VERSION "created by canmatrix"

NS_ :

BS_:

BU_: User ADM_PC_LL25 ADM_PC_BC25 ADM_PC_BP25 ADM_PC_BI25

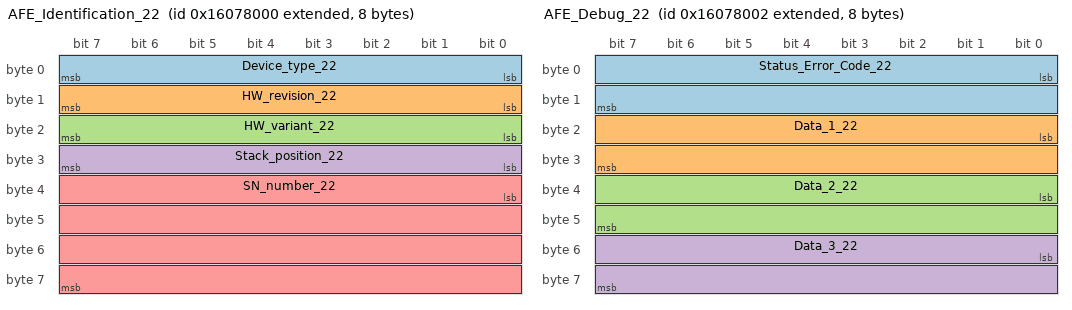
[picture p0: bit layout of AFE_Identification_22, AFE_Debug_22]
BO_ 2517073920 AFE_Identification_22: 8 ADM_PC_BP25
 SG_ Device_type_22 : 0|8@1+ (1,0) [0|255] "" Vector__XXX
 SG_ HW_revision_22 : 8|8@1+ (1,0) [0|255] "" Vector__XXX
 SG_ HW_variant_22 : 16|8@1+ (1,0) [0|255] "" Vector__XXX
 SG_ Stack_position_22 : 24|8@1+ (1,0) [0|255] "" Vector__XXX
 SG_ SN_number_22 : 32|32@1+ (1,0) [0|4294967295] "" Vector__XXX

BO_ 2517073921 AFE_FwInfo_22: 8 ADM_PC_BP25
 SG_ FW_info_mux_22 M : 56|8@1+ (1,0) [0|255] "" Vector__XXX
 SG_ FW_revision_0_22 m0 : 0|8@1+ (1,0) [0|255] "" Vector__XXX
 SG_ FW_revision_1_22 m0 : 8|8@1+ (1,0) [0|255] "" Vector__XXX
 SG_ FW_revision_2_22 m0 : 16|8@1+ (1,0) [0|255] "" Vector__XXX
 SG_ FW_revision_3_22 m0 : 24|8@1+ (1,0) [0|255] "" Vector__XXX
 SG_ FW_revision_4_22 m0 : 32|8@1+ (1,0) [0|255] "" Vector__XXX
 SG_ FW_revision_5_22 m0 : 40|8@1+ (1,0) [0|255] "" Vector__XXX
 SG_ FW_revision_6_22 m0 : 48|8@1+ (1,0) [0|255] "" Vector__XXX
 SG_ FW_revision_7_22 m1 : 0|8@1+ (1,0) [0|255] "" Vector__XXX
 SG_ FW_revision_8_22 m1 : 8|8@1+ (1,0) [0|255] "" Vector__XXX
 SG_ FW_revision_9_22 m1 : 16|8@1+ (1,0) [0|255] "" Vector__XXX
 SG_ FW_revision_10_22 m1 : 24|8@1+ (1,0) [0|255] "" Vector__XXX
 SG_ FW_revision_11_22 m1 : 32|8@1+ (1,0) [0|255] "" Vector__XXX
 SG_ FW_revision_12_22 m1 : 40|8@1+ (1,0) [0|255] "" Vector__XXX
 SG_ FW_revision_13_22 m1 : 48|8@1+ (1,0) [0|255] "" Vector__XXX
 SG_ FW_datecode_0_22 m2 : 0|8@1+ (1,0) [0|255] "" Vector__XXX
 SG_ FW_datecode_1_22 m2 : 8|8@1+ (1,0) [0|255] "" Vector__XXX
 SG_ FW_datecode_2_22 m2 : 16|8@1+ (1,0) [0|255] "" Vector__XXX
 SG_ FW_datecode_3_22 m2 : 24|8@1+ (1,0) [0|255] "" Vector__XXX
 SG_ FW_datecode_4_22 m2 : 32|8@1+ (1,0) [0|255] "" Vector__XXX
 SG_ FW_datecode_5_22 m2 : 40|8@1+ (1,0) [0|255] "" Vector__XXX
 SG_ FW_datecode_6_22 m2 : 48|8@1+ (1,0) [0|255] "" Vector__XXX
 SG_ FW_datecode_7_22 m3 : 0|8@1+ (1,0) [0|255] "" Vector__XXX
 SG_ FW_datecode_8_22 m3 : 8|8@1+ (1,0) [0|255] "" Vector__XXX
 SG_ FW_datecode_9_22 m3 : 16|8@1+ (1,0) [0|255] "" Vector__XXX
 SG_ FW_datecode_10_22 m3 : 24|8@1+ (1,0) [0|255] "" Vector__XXX
 SG_ FW_datecode_11_22 m3 : 32|8@1+ (1,0) [0|255] "" Vector__XXX
 SG_ FW_datecode_12_22 m3 : 40|8@1+ (1,0) [0|255] "" Vector__XXX
 SG_ FW_datecode_13_22 m3 : 48|8@1+ (1,0) [0|255] "" Vector__XXX

BO_ 2517073933 _AFE_Boot_FwInfo_22: 8 ADM_PC_BP25
 SG_ Boot_FW_info_mux_22 M : 56|8@1+ (1,0) [0|255] "" Vector__XXX
 SG_ FW_revision_0_22 m0 : 0|8@1+ (1,0) [0|255] "" Vector__XXX
 SG_ FW_revision_1_22 m0 : 8|8@1+ (1,0) [0|255] "" Vector__XXX
 SG_ FW_revision_2_22 m0 : 16|8@1+ (1,0) [0|255] "" Vector__XXX
 SG_ FW_revision_3_22 m0 : 24|8@1+ (1,0) [0|255] "" Vector__XXX
 SG_ FW_revision_4_22 m0 : 32|8@1+ (1,0) [0|255] "" Vector__XXX
 SG_ FW_revision_5_22 m0 : 40|8@1+ (1,0) [0|255] "" Vector__XXX
 SG_ FW_revision_6_22 m0 : 48|8@1+ (1,0) [0|255] "" Vector__XXX
 SG_ FW_revision_7_22 m1 : 0|8@1+ (1,0) [0|255] "" Vector__XXX
 SG_ FW_revision_8_22 m1 : 8|8@1+ (1,0) [0|255] "" Vector__XXX
 SG_ FW_revision_9_22 m1 : 16|8@1+ (1,0) [0|255] "" Vector__XXX
 SG_ FW_revision_10_22 m1 : 24|8@1+ (1,0) [0|255] "" Vector__XXX
 SG_ FW_revision_11_22 m1 : 32|8@1+ (1,0) [0|255] "" Vector__XXX
 SG_ FW_revision_12_22 m1 : 40|8@1+ (1,0) [0|255] "" Vector__XXX
 SG_ FW_revision_13_22 m1 : 48|8@1+ (1,0) [0|255] "" Vector__XXX
 SG_ FW_datecode_0_22 m2 : 0|8@1+ (1,0) [0|255] "" Vector__XXX
 SG_ FW_datecode_1_22 m2 : 8|8@1+ (1,0) [0|255] "" Vector__XXX
 SG_ FW_datecode_2_22 m2 : 16|8@1+ (1,0) [0|255] "" Vector__XXX
 SG_ FW_datecode_3_22 m2 : 24|8@1+ (1,0) [0|255] "" Vector__XXX
 SG_ FW_datecode_4_22 m2 : 32|8@1+ (1,0) [0|255] "" Vector__XXX
 SG_ FW_datecode_5_22 m2 : 40|8@1+ (1,0) [0|255] "" Vector__XXX
 SG_ FW_datecode_6_22 m2 : 48|8@1+ (1,0) [0|255] "" Vector__XXX
 SG_ FW_datecode_7_22 m3 : 0|8@1+ (1,0) [0|255] "" Vector__XXX
 SG_ FW_datecode_8_22 m3 : 8|8@1+ (1,0) [0|255] "" Vector__XXX
 SG_ FW_datecode_9_22 m3 : 16|8@1+ (1,0) [0|255] "" Vector__XXX
 SG_ FW_datecode_10_22 m3 : 24|8@1+ (1,0) [0|255] "" Vector__XXX
 SG_ FW_datecode_11_22 m3 : 32|8@1+ (1,0) [0|255] "" Vector__XXX
 SG_ FW_datecode_12_22 m3 : 40|8@1+ (1,0) [0|255] "" Vector__XXX
 SG_ FW_datecode_13_22 m3 : 48|8@1+ (1,0) [0|255] "" Vector__XXX

BO_ 2517073922 AFE_Debug_22: 8 ADM_PC_BP25
 SG_ Status_Error_Code_22 : 0|16@1+ (1,0) [0|65535] "" Vector__XXX
 SG_ Data_1_22 : 16|16@1+ (1,0) [0|65535] "" Vector__XXX
 SG_ Data_2_22 : 32|16@1+ (1,0) [0|65535] "" Vector__XXX
 SG_ Data_3_22 : 48|16@1+ (1,0) [0|65535] "" Vector__XXX

BO_ 2517073927 AFE_Status_22: 8 ADM_PC_BP25
 SG_ Running_22 : 0|1@1+ (1,0) [0|1] "" Vector__XXX
 SG_ PWM_22 : 1|1@1+ (1,0) [0|1] "" Vector__XXX
 SG_ Current_dc_loop_mode_22 : 2|1@1+ (1,0) [0|1] "" Vector__XXX
 SG_ Current_ac_loop_mode_22 : 3|1@1+ (1,0) [0|1] "" Vector__XXX
 SG_ Buck_22 : 5|1@1+ (1,0) [0|1] "" Vector__XXX
 SG_ Boost_22 : 6|1@1+ (1,0) [0|1] "" Vector__XXX
 SG_ Precharge_dc_buck_mode_22 : 7|1@1+ (1,0) [0|1] "" Vector__XXX
 SG_ Precharge_dc_boost_mode_22 : 8|1@1+ (1,0) [0|1] "" Vector__XXX
 SG_ Rectifier_3ph_22 : 9|1@1+ (1,0) [0|1] "" Vector__XXX
 SG_ Stack_mode_22 : 10|1@1+ (1,0) [0|1] "" Vector__XXX
 SG_ Master_22 : 11|1@1+ (1,0) [0|1] "" Vector__XXX
 SG_ Slave_22 : 12|1@1+ (1,0) [0|1] "" Vector__XXX
 SG_ Inverter_1ph_22 : 13|1@1+ (1,0) [0|1] "" Vector__XXX
 SG_ Boost_Neutral_22 : 14|1@1+ (1,0) [0|1] "" Vector__XXX
 SG_ Rectifier_1ph_22 : 15|1@1+ (1,0) [0|1] "" Vector__XXX
 SG_ Inverter_3ph_22 : 16|1@1+ (1,0) [0|1] "" Vector__XXX
 SG_ Ready_22 : 17|1@1+ (1,0) [0|1] "" Vector__XXX
 SG_ Inverter_1ph_Sync_22 : 18|1@1+ (1,0) [0|1] "" Vector__XXX
 SG_ Neutral_22 : 19|1@1+ (1,0) [0|1] "" Vector__XXX
 SG_ Rectifier_1ph_Buck_22 : 20|1@1+ (1,0) [0|1] "" Vector__XXX
 SG_ Inverter_1ph_Boost_22 : 21|1@1+ (1,0) [0|1] "" Vector__XXX
 SG_ Rectifier_distributed_22 : 22|1@1+ (1,0) [0|1] "" Vector__XXX
 SG_ MPPT_buck_22 : 23|1@1+ (1,0) [0|1] "" Vector__XXX
 SG_ MPPT_boost_22 : 24|1@1+ (1,0) [0|1] "" Vector__XXX
 SG_ Buck_2p_float_22 : 25|1@1+ (1,0) [0|1] "" Vector__XXX
 SG_ Inverter_1ph_Distributed_22 : 26|1@1+ (1,0) [0|1] "" Vector__XXX

BO_ 2517073926 AFE_Faults_22: 3 ADM_PC_BP25
 SG_ Protection_trip_internal_22 : 0|1@1+ (1,0) [0|1] "" Vector__XXX
 SG_ Protection_trip_external_22 : 1|1@1+ (1,0) [0|1] "" Vector__XXX
 SG_ Phase_U_overcurrent_22 : 2|1@1+ (1,0) [0|1] "" Vector__XXX
 SG_ Phase_U_overvoltage_22 : 3|1@1+ (1,0) [0|1] "" Vector__XXX
 SG_ Phase_U_undervoltage_22 : 4|1@1+ (1,0) [0|1] "" Vector__XXX
 SG_ Phase_V_overvoltage_22 : 5|1@1+ (1,0) [0|1] "" Vector__XXX
 SG_ Phase_V_undervoltage_22 : 6|1@1+ (1,0) [0|1] "" Vector__XXX
 SG_ Phase_V_overcurrent_22 : 7|1@1+ (1,0) [0|1] "" Vector__XXX
 SG_ Phase_W_overvoltage_22 : 8|1@1+ (1,0) [0|1] "" Vector__XXX
 SG_ Phase_W_undervoltage_22 : 9|1@1+ (1,0) [0|1] "" Vector__XXX
 SG_ Phase_W_overcurrent_22 : 10|1@1+ (1,0) [0|1] "" Vector__XXX
 SG_ DC_undervoltage_22 : 11|1@1+ (1,0) [0|1] "" Vector__XXX
 SG_ DC_overvoltage_22 : 12|1@1+ (1,0) [0|1] "" Vector__XXX
 SG_ MOSFET_overtemperature_22 : 13|1@1+ (1,0) [0|1] "" Vector__XXX
 SG_ Inductor_overtemperature_22 : 14|1@1+ (1,0) [0|1] "" Vector__XXX
 SG_ Keep_Alive_not_served_22 : 15|1@1+ (1,0) [0|1] "" Vector__XXX
 SG_ PLL_not_locked_22 : 16|1@1+ (1,0) [0|1] "" Vector__XXX
 SG_ NFO_22 : 20|1@1+ (1,0) [0|1] "" Vector__XXX
 SG_ Measurement_system_failure_22 : 21|1@1+ (1,0) [0|1] "" Vector__XXX
 SG_ EEPROM_failure_22 : 22|1@1+ (1,0) [0|1] "" Vector__XXX
 SG_ System_22 : 23|1@1+ (1,0) [0|1] "" Vector__XXX

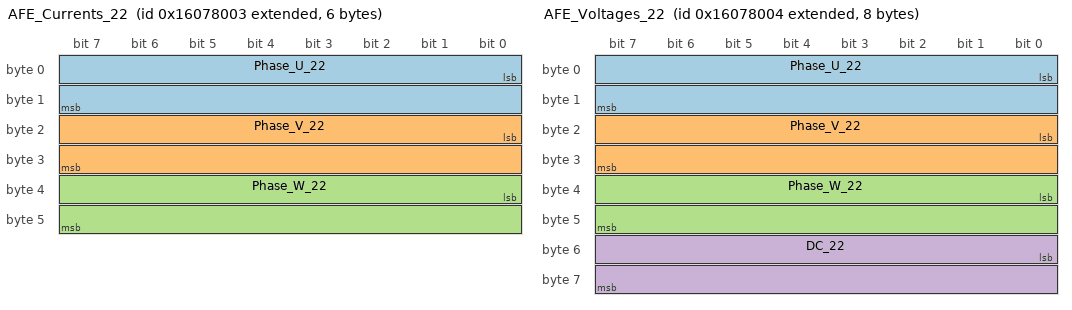
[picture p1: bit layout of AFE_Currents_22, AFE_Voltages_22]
BO_ 2517073923 AFE_Currents_22: 6 ADM_PC_BP25
 SG_ Phase_U_22 : 0|16@1- (0.01,0) [-327.68|327.67] "A" Vector__XXX
 SG_ Phase_V_22 : 16|16@1- (0.01,0) [-327.68|327.67] "A" Vector__XXX
 SG_ Phase_W_22 : 32|16@1- (0.01,0) [-327.68|327.67] "A" Vector__XXX

BO_ 2517073936 AFE_DC_Bus_current_22: 2 ADM_PC_BP25
 SG_ Bus_current_22 : 0|16@1- (0.01,0) [-327.68|327.67] "A" Vector__XXX

BO_ 2517073934 _AFE_Broadcast_22: 8 ADM_PC_BP25
 SG_ Diagnostics_Index_22 M : 56|8@1+ (1,0) [0|255] "" Vector__XXX
 SG_ Phase_U_22 m1 : 8|16@1- (0.01,0) [-327.68|327.67] "A" ADM_PC_BP25
 SG_ Phase_V_22 m1 : 24|16@1- (0.01,0) [-327.68|327.67] "A" ADM_PC_BP25
 SG_ Phase_W_22 m1 : 40|16@1- (0.01,0) [-327.68|327.67] "A" ADM_PC_BP25
 SG_ Stack_position_22 : 0|5@1+ (1,0) [0|31] "" ADM_PC_BP25
 SG_ Group_ID_22 : 5|3@1+ (1,0) [0|7] "" ADM_PC_BP25

BO_ 2517073924 AFE_Voltages_22: 8 ADM_PC_BP25
 SG_ Phase_U_22 : 0|16@1- (0.1,0) [-3276.8|3276.7] "V" Vector__XXX
 SG_ Phase_V_22 : 16|16@1- (0.1,0) [-3276.8|3276.7] "V" Vector__XXX
 SG_ Phase_W_22 : 32|16@1- (0.1,0) [-3276.8|3276.7] "V" Vector__XXX
 SG_ DC_22 : 48|16@1- (0.1,0) [-3276.8|3276.7] "V" Vector__XXX

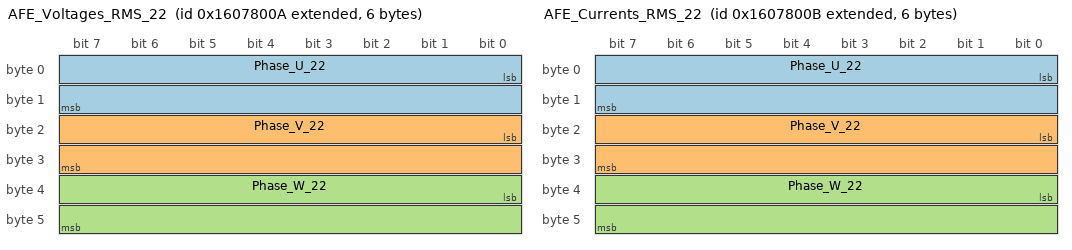
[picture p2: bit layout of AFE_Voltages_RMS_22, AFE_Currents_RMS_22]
BO_ 2517073930 AFE_Voltages_RMS_22: 6 ADM_PC_BP25
 SG_ Phase_U_22 : 0|16@1+ (0.1,0) [0|6553.5] "V" Vector__XXX
 SG_ Phase_V_22 : 16|16@1+ (0.1,0) [0|6553.5] "V" Vector__XXX
 SG_ Phase_W_22 : 32|16@1+ (0.1,0) [0|6553.5] "V" Vector__XXX

BO_ 2517073931 AFE_Currents_RMS_22: 6 ADM_PC_BP25
 SG_ Phase_U_22 : 0|16@1+ (0.01,0) [0.00|655.35] "A" Vector__XXX
 SG_ Phase_V_22 : 16|16@1+ (0.01,0) [0.00|655.35] "A" Vector__XXX
 SG_ Phase_W_22 : 32|16@1+ (0.01,0) [0.00|655.35] "A" Vector__XXX

BO_ 2517073932 AFE_Mains_22: 4 ADM_PC_BP25
 SG_ Frequency_22 : 0|16@1+ (0.01,0) [0.00|655.35] "Hz" Vector__XXX
 SG_ Phase_22 : 16|16@1- (0.1,0) [-3276.8|3276.7] "Deg." Vector__XXX

BO_ 2517073925 AFE_Temperatures_22: 4 ADM_PC_BP25
 SG_ Temp_Bridge_22 : 0|16@1- (0.01,0) [-327.68|327.67] "°C" Vector__XXX
 SG_ Temp_Inductors_22 : 16|16@1- (0.01,0) [-327.68|327.67] "°C" Vector__XXX

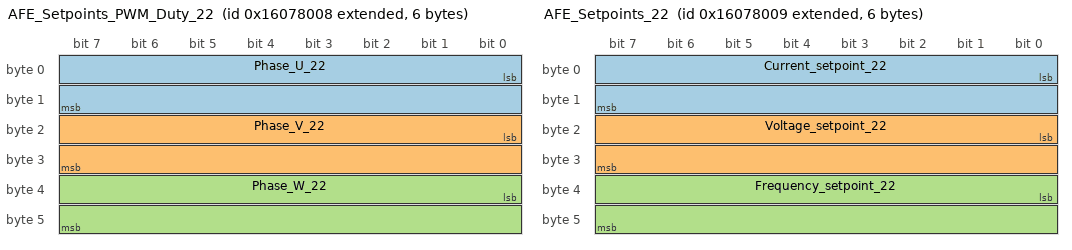
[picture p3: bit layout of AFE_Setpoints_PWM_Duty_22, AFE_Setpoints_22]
BO_ 2517073928 AFE_Setpoints_PWM_Duty_22: 6 ADM_PC_BP25
 SG_ Phase_U_22 : 0|16@1+ (0.001525902,0) [0E-009|99.999987570] "%" Vector__XXX
 SG_ Phase_V_22 : 16|16@1+ (0.001525902,0) [0E-009|99.999987570] "%" Vector__XXX
 SG_ Phase_W_22 : 32|16@1+ (0.001525902,0) [0E-009|99.999987570] "%" Vector__XXX

BO_ 2517073929 AFE_Setpoints_22: 6 ADM_PC_BP25
 SG_ Current_setpoint_22 : 0|16@1- (0.01,0) [-327.68|327.67] "A" Vector__XXX
 SG_ Voltage_setpoint_22 : 16|16@1+ (0.1,0) [0|6553.5] "V" Vector__XXX
 SG_ Frequency_setpoint_22 : 32|16@1+ (0.01,0) [0.00|655.35] "Hz" Vector__XXX

BO_ 2517041248 AFE_Keep_Alive_22: 1 User
 SG_ Keep_Alive_Enable_22 : 0|1@1+ (1,0) [0|1] "" ADM_PC_BP25

BO_ 2517041216 AFE_Mode_Control_22: 8 User
 SG_ Converter_ON_22 : 0|1@1+ (1,0) [0|1] "" ADM_PC_BP25
 SG_ PWM_ON_22 : 1|1@1+ (1,0) [0|1] "" ADM_PC_BP25
 SG_ DC_Current_feedback_ON_22 : 2|1@1+ (1,0) [0|1] "" ADM_PC_BP25
 SG_ AC_Current_feedback_ON_22 : 3|1@1+ (1,0) [0|1] "" ADM_PC_BP25
 SG_ Buck_ON_22 : 5|1@1+ (1,0) [0|1] "" ADM_PC_BP25
 SG_ Boost_ON_22 : 6|1@1+ (1,0) [0|1] "" ADM_PC_BP25
 SG_ Rectifier_3ph_ON_22 : 9|1@1+ (1,0) [0|1] "" ADM_PC_BP25
 SG_ Inverter_1ph_ON_22 : 10|1@1+ (1,0) [0|1] "" ADM_PC_BP25
 SG_ Rectifier_1ph_ON_22 : 11|1@1+ (1,0) [0|1] "" ADM_PC_BP25
 SG_ Boost_Neutral_ON_22 : 12|1@1+ (1,0) [0|1] "" ADM_PC_BP25
 SG_ Inverter_3ph_ON_22 : 13|1@1+ (1,0) [0|1] "" ADM_PC_BP25
 SG_ Inverter_1ph_Sync_ON_22 : 14|1@1+ (1,0) [0|1] "" ADM_PC_BP25
 SG_ Neutral_ON_22 : 15|1@1+ (1,0) [0|1] "" ADM_PC_BP25
 SG_ Rectifier_1ph_Buck_ON_22 : 16|1@1+ (1,0) [0|1] "" ADM_PC_BP25
 SG_ Inverter_1ph_Boost_ON_22 : 17|1@1+ (1,0) [0|1] "" ADM_PC_BP25
 SG_ Rectifier_Distributed_ON_22 : 18|1@1+ (1,0) [0|1] "" ADM_PC_BP25
 SG_ MPPT_buck_ON_22 : 19|1@1+ (1,0) [0|1] "" ADM_PC_BP25
 SG_ MPPT_boost_ON_22 : 20|1@1+ (1,0) [0|1] "" ADM_PC_BP25
 SG_ Buck_2p_float_ON_22 : 21|1@1+ (1,0) [0|1] "" ADM_PC_BP25
 SG_ Inverter_1ph_Distributed_ON_22 : 22|1@1+ (1,0) [0|1] "" ADM_PC_BP25

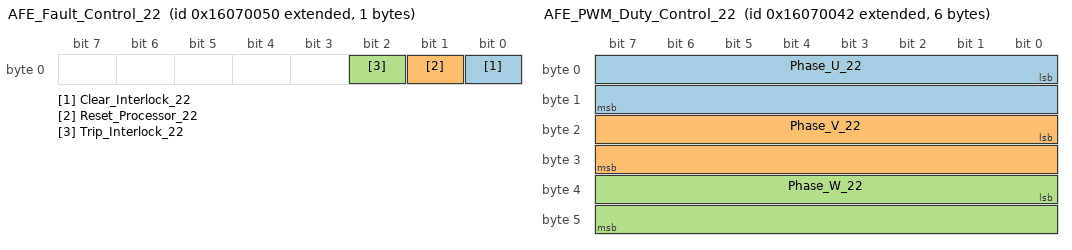
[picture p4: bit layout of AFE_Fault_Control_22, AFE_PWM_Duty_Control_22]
BO_ 2517041232 AFE_Fault_Control_22: 1 User
 SG_ Clear_Interlock_22 : 0|1@1+ (1,0) [0|1] "" ADM_PC_BP25
 SG_ Reset_Processor_22 : 1|1@1+ (1,0) [0|1] "" ADM_PC_BP25
 SG_ Trip_Interlock_22 : 2|1@1+ (1,0) [0|1] "" ADM_PC_BP25

BO_ 2517041217 AFE_Reactive_Current_Setpoint_Co: 2 User
 SG_ Reactive_current_setpoint_22 : 0|16@1- (0.01,0) [-150|150] "A" ADM_PC_BP25

BO_ 2517041218 AFE_PWM_Duty_Control_22: 6 User
 SG_ Phase_U_22 : 0|16@1+ (0.001525902,0) [0E-009|99.999987570] "%" ADM_PC_BP25
 SG_ Phase_V_22 : 16|16@1+ (0.001525902,0) [0E-009|99.999987570] "%" ADM_PC_BP25
 SG_ Phase_W_22 : 32|16@1+ (0.001525902,0) [0E-009|99.999987570] "%" ADM_PC_BP25

BO_ 2517041219 AFE_Current_Setpoint_Control_22: 2 User
 SG_ Current_setpoint_22 : 0|16@1- (0.01,0) [-150|150] "A" ADM_PC_BP25

BO_ 2517041220 AFE_Voltage_Setpoint_Control_22: 2 User
 SG_ Voltage_setpoint_22 : 0|16@1+ (0.1,0) [0|1500] "V" ADM_PC_BP25

BO_ 2517041224 AFE_Frequency_Setpoint_Control_2: 2 User
 SG_ Frequency_setpoint_22 : 0|16@1+ (0.01,0) [40|70] "Hz" ADM_PC_BP25

BO_ 2517041225 AFE_Phase_Setpoint_Control_22: 2 User
 SG_ Phase_setpoint_22 : 0|16@1+ (1,0) [0|360] "deg" ADM_PC_BP25

BO_ 2517041264 AFE_Rectifier_Setpoint_Control_2: 8 User
 SG_ Voltage_setpoint_2_22 : 0|16@1+ (0.1,0) [0|1500] "V" ADM_PC_BP25
 SG_ Current_setpoint_2_22 : 16|16@1- (0.01,0) [-150|150] "A" ADM_PC_BP25

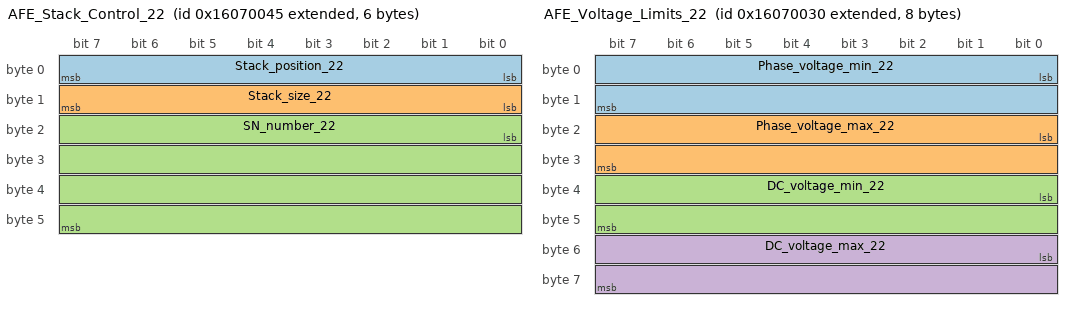
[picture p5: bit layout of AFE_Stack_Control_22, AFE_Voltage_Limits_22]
BO_ 2517041221 AFE_Stack_Control_22: 6 User
 SG_ Stack_position_22 : 0|8@1+ (1,0) [0|255] "" ADM_PC_BP25
 SG_ Stack_size_22 : 8|8@1+ (1,0) [0|255] "" ADM_PC_BP25
 SG_ SN_number_22 : 16|32@1+ (1,0) [0|4294967295] "" ADM_PC_BP25

BO_ 2517041200 AFE_Voltage_Limits_22: 8 User
 SG_ Phase_voltage_min_22 : 0|16@1- (0.1,0) [0|3276.7] "V" ADM_PC_BP25
 SG_ Phase_voltage_max_22 : 16|16@1- (0.1,0) [-3276.8|850] "V" ADM_PC_BP25
 SG_ DC_voltage_min_22 : 32|16@1- (0.1,0) [0|3276.7] "V" ADM_PC_BP25
 SG_ DC_voltage_max_22 : 48|16@1- (0.1,0) [-3276.8|850] "V" ADM_PC_BP25

BO_ 2517041201 AFE_Current_Limits_22: 4 User
 SG_ Phase_current_min_22 : 0|16@1- (0.01,0) [-60|60] "A" ADM_PC_BP25
 SG_ Phase_current_max_22 : 16|16@1- (0.01,0) [-60|60] "A" ADM_PC_BP25

BO_ 2517041228 AFE_Group_Control_22: 1 User
 SG_ Group_ID_22 : 0|8@1+ (1,0) [0|255] "" ADM_PC_BP25

BO_ 2517073935 AFE_Group_Info_22: 1 ADM_PC_BP25
 SG_ Group_ID_22 : 0|8@1+ (1,0) [0|255] "" Vector__XXX

BO_ 2517041249 AFE_System_Flags_Control_22: 8 User
 SG_ Factory_mode_22 : 0|1@1+ (1,0) [0|1] "" ADM_PC_BP25
 SG_ Silent_CAN_mode_22 : 1|1@1+ (1,0) [0|1] "" ADM_PC_BP25

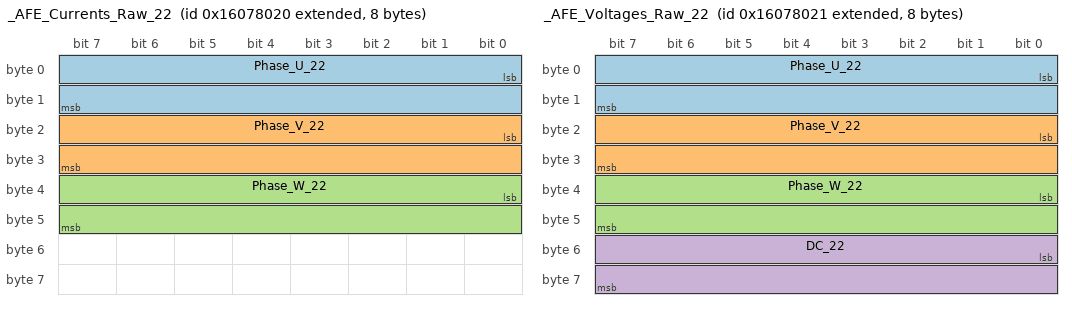
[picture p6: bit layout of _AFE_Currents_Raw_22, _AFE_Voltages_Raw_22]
BO_ 2517073952 _AFE_Currents_Raw_22: 8 ADM_PC_BP25
 SG_ Phase_U_22 : 0|16@1- (1,0) [-32768|32767] "" Vector__XXX
 SG_ Phase_V_22 : 16|16@1- (1,0) [-32768|32767] "" Vector__XXX
 SG_ Phase_W_22 : 32|16@1- (1,0) [-32768|32767] "" Vector__XXX

BO_ 2517073953 _AFE_Voltages_Raw_22: 8 ADM_PC_BP25
 SG_ Phase_U_22 : 0|16@1- (1,0) [-32768|32767] "" Vector__XXX
 SG_ Phase_V_22 : 16|16@1- (1,0) [-32768|32767] "" Vector__XXX
 SG_ Phase_W_22 : 32|16@1- (1,0) [-32768|32767] "" Vector__XXX
 SG_ DC_22 : 48|16@1- (1,0) [-32768|32767] "" Vector__XXX

BO_ 2517041226 _AFE_ADC_Calibration_Mode_22: 1 User
 SG_ Calibration_Index_22 M : 2|5@1+ (1,0) [0|31] "" Vector__XXX
 SG_ Current_U_22 m1 : 0|2@1+ (1,0) [0|3] "" ADM_PC_BP25
 SG_ Current_V_22 m2 : 0|2@1+ (1,0) [0|3] "" ADM_PC_BP25
 SG_ Current_W_22 m3 : 0|2@1+ (1,0) [0|3] "" ADM_PC_BP25
 SG_ Voltage_U_22 m4 : 0|2@1+ (1,0) [0|3] "" ADM_PC_BP25
 SG_ Voltage_V_22 m5 : 0|2@1+ (1,0) [0|3] "" ADM_PC_BP25
 SG_ Voltage_W_22 m6 : 0|2@1+ (1,0) [0|3] "" ADM_PC_BP25
 SG_ Voltage_DC_22 m7 : 0|2@1+ (1,0) [0|3] "" ADM_PC_BP25
 SG_ start_22 : 7|1@1+ (1,0) [0|1] "" ADM_PC_BP25

BO_ 2517041227 _AFE_ADC_Calibration_Setpoint_22: 3 User
 SG_ Calibration_Index_22 M : 16|5@1+ (1,0) [0|31] "" Vector__XXX
 SG_ Current_U_22 m1 : 0|16@1- (0.01,0) [-100|100] "A" ADM_PC_BP25
 SG_ Current_V_22 m2 : 0|16@1- (0.01,0) [-100|100] "A" ADM_PC_BP25
 SG_ Current_W_22 m3 : 0|16@1- (0.01,0) [-100|100] "A" ADM_PC_BP25
 SG_ Voltage_U_22 m4 : 0|16@1+ (0.1,0) [0|1500] "V" ADM_PC_BP25
 SG_ Voltage_V_22 m5 : 0|16@1+ (0.1,0) [0|1500] "V" ADM_PC_BP25
 SG_ Voltage_W_22 m6 : 0|16@1+ (0.1,0) [0|1500] "V" ADM_PC_BP25
 SG_ Voltage_DC_22 m7 : 0|16@1+ (0.1,0) [0|1500] "V" ADM_PC_BP25
 SG_ point_22 : 21|3@1+ (1,0) [0|7] "" ADM_PC_BP25

BO_ 2517041222 _AFE_Calibration_Offset_Update_2: 6 User
 SG_ Calibration_Index_22 M : 16|16@1+ (1,0) [0|65535] "" Vector__XXX
 SG_ Current_U_22 m0 : 0|16@1- (1,0) [-32768|32767] "ADC Counts" ADM_PC_BP25
 SG_ Current_V_22 m1 : 0|16@1- (1,0) [-32768|32767] "ADC Counts" ADM_PC_BP25
 SG_ Current_W_22 m2 : 0|16@1- (1,0) [-32768|32767] "ADC Counts" ADM_PC_BP25
 SG_ Voltage_U_22 m3 : 0|16@1- (1,0) [-32768|32767] "ADC Counts" ADM_PC_BP25
 SG_ Voltage_V_22 m4 : 0|16@1- (1,0) [-32768|32767] "ADC Counts" ADM_PC_BP25
 SG_ Voltage_W_22 m5 : 0|16@1- (1,0) [-32768|32767] "ADC Counts" ADM_PC_BP25
 SG_ Voltage_DC_22 m6 : 0|16@1- (1,0) [-32768|32767] "ADC Counts" ADM_PC_BP25
 SG_ CRC_22 : 32|16@1+ (1,0) [0|65535] "-" ADM_PC_BP25

BO_ 2517041223 _AFE_Calibration_Scale_Update_22: 6 User
 SG_ Calibration_Index_22 M : 16|16@1+ (1,0) [0|65535] "" Vector__XXX
 SG_ Current_U_22 m0 : 0|16@1- (0.0000152587890625,0) [-0.5000000000000000|0.4999847412109375] "scale = 1.0 + value" ADM_PC_BP25
 SG_ Current_V_22 m1 : 0|16@1- (0.0000152587890625,0) [-0.5000000000000000|0.4999847412109375] "scale = 1.0 + value" ADM_PC_BP25
 SG_ Current_W_22 m2 : 0|16@1- (0.0000152587890625,0) [-0.5000000000000000|0.4999847412109375] "scale = 1.0 + value" ADM_PC_BP25
 SG_ Voltage_U_22 m3 : 0|16@1- (0.0000152587890625,0) [-0.5000000000000000|0.4999847412109375] "scale = 1.0 + value" ADM_PC_BP25
 SG_ Voltage_V_22 m4 : 0|16@1- (0.0000152587890625,0) [-0.5000000000000000|0.4999847412109375] "scale = 1.0 + value" ADM_PC_BP25
 SG_ Voltage_W_22 m5 : 0|16@1- (0.0000152587890625,0) [-0.5000000000000000|0.4999847412109375] "scale = 1.0 + value" ADM_PC_BP25
 SG_ Voltage_DC_22 m6 : 0|16@1- (0.0000152587890625,0) [-0.5000000000000000|0.4999847412109375] "scale = 1.0 + value" ADM_PC_BP25
 SG_ CRC_22 : 32|16@1+ (1,0) [0|65535] "-" ADM_PC_BP25

BO_ 2517074001 _AFE_Calibration_Adc_Scale_22: 6 ADM_PC_BP25
 SG_ Adc_Index_22 M : 32|16@1+ (1,0) [0|65535] "" Vector__XXX
 SG_ Current_U_22 m0 : 0|32@1+ (1,0) [0|4294967295] "1 / adc_bins" User
 SG_ Current_V_22 m1 : 0|32@1+ (1,0) [0|4294967295] "1 / adc_bins" User
 SG_ Current_W_22 m2 : 0|32@1+ (1,0) [0|4294967295] "1 / adc_bins" User
 SG_ Voltage_U_22 m3 : 0|32@1+ (1,0) [0|4294967295] "1 / adc_bins" User
 SG_ Voltage_V_22 m4 : 0|32@1+ (1,0) [0|4294967295] "1 / adc_bins" User
 SG_ Voltage_W_22 m5 : 0|32@1+ (1,0) [0|4294967295] "1 / adc_bins" User
 SG_ Voltage_DC_22 m6 : 0|32@1+ (1,0) [0|4294967295] "1 / adc_bins" User

BO_ 2517074002 _AFE_Calibration_Adc_Fs_22: 6 ADM_PC_BP25
 SG_ Adc_Index_22 M : 32|16@1+ (1,0) [0|65535] "" Vector__XXX
 SG_ Current_U_22 m0 : 0|32@1+ (1,0) [0|4294967295] "Fullscale" User
 SG_ Current_V_22 m1 : 0|32@1+ (1,0) [0|4294967295] "Fullscale" User
 SG_ Current_W_22 m2 : 0|32@1+ (1,0) [0|4294967295] "Fullscale" User
 SG_ Voltage_U_22 m3 : 0|32@1+ (1,0) [0|4294967295] "Fullscale" User
 SG_ Voltage_V_22 m4 : 0|32@1+ (1,0) [0|4294967295] "Fullscale" User
 SG_ Voltage_W_22 m5 : 0|32@1+ (1,0) [0|4294967295] "Fullscale" User
 SG_ Voltage_DC_22 m6 : 0|32@1+ (1,0) [0|4294967295] "Fullscale" User

BO_ 2517074003 _AFE_Calibration_Adc_Offset_22: 4 ADM_PC_BP25
 SG_ Adc_Index_22 M : 16|16@1+ (1,0) [0|65535] "" Vector__XXX
 SG_ Current_U_22 m0 : 0|16@1- (1,0) [-32768|32767] "-" User
 SG_ Current_V_22 m1 : 0|16@1- (1,0) [-32768|32767] "-" User
 SG_ Current_W_22 m2 : 0|16@1- (1,0) [-32768|32767] "-" User
 SG_ Voltage_U_22 m3 : 0|16@1- (1,0) [-32768|32767] "-" User
 SG_ Voltage_V_22 m4 : 0|16@1- (1,0) [-32768|32767] "-" User
 SG_ Voltage_W_22 m5 : 0|16@1- (1,0) [-32768|32767] "-" User
 SG_ Voltage_DC_22 m6 : 0|16@1- (1,0) [-32768|32767] "-" User

BO_ 2517074004 _AFE_Calibration_Adc_Gain_22: 4 ADM_PC_BP25
 SG_ Adc_Index_22 M : 16|16@1+ (1,0) [0|65535] "" Vector__XXX
 SG_ Current_U_22 m0 : 0|16@1- (1,0) [-32768|32767] "-" User
 SG_ Current_V_22 m1 : 0|16@1- (1,0) [-32768|32767] "-" User
 SG_ Current_W_22 m2 : 0|16@1- (1,0) [-32768|32767] "-" User
 SG_ Voltage_U_22 m3 : 0|16@1- (1,0) [-32768|32767] "-" User
 SG_ Voltage_V_22 m4 : 0|16@1- (1,0) [-32768|32767] "-" User
 SG_ Voltage_W_22 m5 : 0|16@1- (1,0) [-32768|32767] "-" User
 SG_ Voltage_DC_22 m6 : 0|16@1- (1,0) [-32768|32767] "-" User

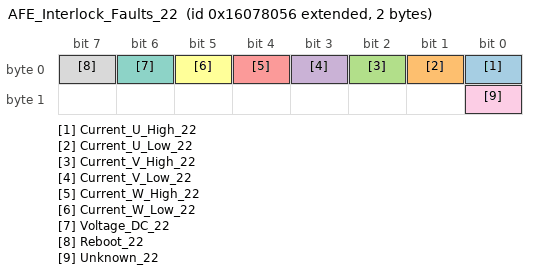
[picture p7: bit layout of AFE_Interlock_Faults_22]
BO_ 2517074006 AFE_Interlock_Faults_22: 2 ADM_PC_BP25
 SG_ Current_U_High_22 : 0|1@1+ (1,0) [0|1] "" Vector__XXX
 SG_ Current_U_Low_22 : 1|1@1+ (1,0) [0|1] "" Vector__XXX
 SG_ Current_V_High_22 : 2|1@1+ (1,0) [0|1] "" Vector__XXX
 SG_ Current_V_Low_22 : 3|1@1+ (1,0) [0|1] "" Vector__XXX
 SG_ Current_W_High_22 : 4|1@1+ (1,0) [0|1] "" Vector__XXX
 SG_ Current_W_Low_22 : 5|1@1+ (1,0) [0|1] "" Vector__XXX
 SG_ Voltage_DC_22 : 6|1@1+ (1,0) [0|1] "" Vector__XXX
 SG_ Reboot_22 : 7|1@1+ (1,0) [0|1] "" Vector__XXX
 SG_ Unknown_22 : 8|1@1+ (1,0) [0|1] "" Vector__XXX

BO_TX_BU_ 2517041216 : User,ADM_PC_LL25,ADM_PC_BC25,ADM_PC_BI25;
BO_TX_BU_ 2517041219 : User,ADM_PC_LL25,ADM_PC_BC25,ADM_PC_BI25;
BO_TX_BU_ 2517041220 : User,ADM_PC_LL25,ADM_PC_BC25,ADM_PC_BI25;
CM_ BO_ 2517073920  "Identification of the device";
CM_ BO_ 2517073921  "Git revision of the DSP firmware";
CM_ BO_ 2517073933  "Git revision of the bootloader firmware.";
CM_ BO_ 2517073922  "Values for debugging of HW/SW problems";
CM_ BO_ 2517073927  "Status bitfield";
CM_ BO_ 2517073926  "Fault bitfield";
CM_ BO_ 2517073923  "Current of phases U, V, W";
CM_ BO_ 2517073936  "Current of of the DC Bus";
CM_ BO_ 2517073934  "All AFEs will listen to this message";
CM_ BO_ 2517073931  "RMS Current of phases U, V, W";
CM_ BO_ 2517073932  "Three-Phase mains health (frequency, phase...)";
CM_ BO_ 2517073925  "Readouts of the module temperature sensors";
CM_ BO_ 2517073928  "Setpoints";
CM_ BO_ 2517073929  "Setpoints";
CM_ BO_ 2517041248  "Keep alive ping message. ";
CM_ BO_ 2517041216  "Operation Mode control: sets the converter operation mode";
CM_ BO_ 2517041232  "Fault Control: actions to clear faults and reset the system";
CM_ BO_ 2517041217  "Reactive power setpoint control.";
CM_ BO_ 2517041218  "PWM duty cycle control";
CM_ BO_ 2517041219  "Current setpoint control";
CM_ BO_ 2517041220  "Voltage setpoint control";
CM_ BO_ 2517041224  "Frequency setpoint control";
CM_ BO_ 2517041225  "Phase setpoint control";
CM_ BO_ 2517041264  "Additional voltage and current setpoints in single-phase rectifier and inverter control modes.";
CM_ BO_ 2517041221  "PFC stack control";
CM_ BO_ 2517041200  "Set the input and output voltage limits (minimum and maximum)";
CM_ BO_ 2517041201  "Set the output current limits (mminimum and maximum)";
CM_ BO_ 2517041228  "Set the Group ID of the device";
CM_ BO_ 2517073935  "Contains the Group ID of the device";
CM_ BO_ 2517041249  "Control the system flags";
CM_ BO_ 2517073952  "Current of phases A and B";
CM_ BO_ 2517073953  "Current of phases A and B";
CM_ BO_ 2517041226  "Automatic ADC calibration.";
CM_ BO_ 2517041227  "Setpoint for automatic ADC calibration.";
CM_ BO_ 2517041222  "Update of the calibration table for offsets.";
CM_ BO_ 2517041223  "Update of the calibration table for scales.";
CM_ BO_ 2517074001  "
                Adc scale (resolution) value of readouts.
            ";
CM_ BO_ 2517074002  "
                Adc fullscale value of readouts.
            ";
CM_ BO_ 2517074003  "
                Readout of ADC calibration data (offset) from EEPROM.
            ";
CM_ BO_ 2517074004  "
                Readout of ADC calibration data (gain) from EEPROM.
            ";
CM_ BO_ 2517074006  "Fault bitfield";

CM_ SG_ 2517073920 Device_type_22 "The device identification field, uniquely identifies the sender in the network";
CM_ SG_ 2517073920 HW_revision_22 "The hardware revision number";
CM_ SG_ 2517073920 HW_variant_22 "The DSP firmware revision number";
CM_ SG_ 2517073920 Stack_position_22 "Position of the module within the stack";
CM_ SG_ 2517073920 SN_number_22 "Unique module serial number";
CM_ SG_ 2517073921 FW_revision_0_22 "Character 0";
CM_ SG_ 2517073921 FW_revision_1_22 "Character 1";
CM_ SG_ 2517073921 FW_revision_2_22 "Character 2";
CM_ SG_ 2517073921 FW_revision_3_22 "Character 3";
CM_ SG_ 2517073921 FW_revision_4_22 "Character 3";
CM_ SG_ 2517073921 FW_revision_5_22 "Character 3";
CM_ SG_ 2517073921 FW_revision_6_22 "Character 3";
CM_ SG_ 2517073921 FW_revision_7_22 "Character 7";
CM_ SG_ 2517073921 FW_revision_8_22 "Character 8";
CM_ SG_ 2517073921 FW_revision_9_22 "Character 9";
CM_ SG_ 2517073921 FW_revision_10_22 "Character 10";
CM_ SG_ 2517073921 FW_revision_11_22 "Character 11";
CM_ SG_ 2517073921 FW_revision_12_22 "Character 12";
CM_ SG_ 2517073921 FW_revision_13_22 "Character 13";
CM_ SG_ 2517073921 FW_datecode_0_22 "Character 0";
CM_ SG_ 2517073921 FW_datecode_1_22 "Character 1";
CM_ SG_ 2517073921 FW_datecode_2_22 "Character 2";
CM_ SG_ 2517073921 FW_datecode_3_22 "Character 3";
CM_ SG_ 2517073921 FW_datecode_4_22 "Character 3";
CM_ SG_ 2517073921 FW_datecode_5_22 "Character 3";
CM_ SG_ 2517073921 FW_datecode_6_22 "Character 3";
CM_ SG_ 2517073921 FW_datecode_7_22 "Character 7";
CM_ SG_ 2517073921 FW_datecode_8_22 "Character 8";
CM_ SG_ 2517073921 FW_datecode_9_22 "Character 9";
CM_ SG_ 2517073921 FW_datecode_10_22 "Character 10";
CM_ SG_ 2517073921 FW_datecode_11_22 "Character 11";
CM_ SG_ 2517073921 FW_datecode_12_22 "Character 12";
CM_ SG_ 2517073921 FW_datecode_13_22 "Character 13";
CM_ SG_ 2517073933 FW_revision_0_22 "Character 0";
CM_ SG_ 2517073933 FW_revision_1_22 "Character 1";
CM_ SG_ 2517073933 FW_revision_2_22 "Character 2";
CM_ SG_ 2517073933 FW_revision_3_22 "Character 3";
CM_ SG_ 2517073933 FW_revision_4_22 "Character 3";
CM_ SG_ 2517073933 FW_revision_5_22 "Character 3";
CM_ SG_ 2517073933 FW_revision_6_22 "Character 3";
CM_ SG_ 2517073933 FW_revision_7_22 "Character 7";
CM_ SG_ 2517073933 FW_revision_8_22 "Character 8";
CM_ SG_ 2517073933 FW_revision_9_22 "Character 9";
CM_ SG_ 2517073933 FW_revision_10_22 "Character 10";
CM_ SG_ 2517073933 FW_revision_11_22 "Character 11";
CM_ SG_ 2517073933 FW_revision_12_22 "Character 12";
CM_ SG_ 2517073933 FW_revision_13_22 "Character 13";
CM_ SG_ 2517073933 FW_datecode_0_22 "Character 0";
CM_ SG_ 2517073933 FW_datecode_1_22 "Character 1";
CM_ SG_ 2517073933 FW_datecode_2_22 "Character 2";
CM_ SG_ 2517073933 FW_datecode_3_22 "Character 3";
CM_ SG_ 2517073933 FW_datecode_4_22 "Character 3";
CM_ SG_ 2517073933 FW_datecode_5_22 "Character 3";
CM_ SG_ 2517073933 FW_datecode_6_22 "Character 3";
CM_ SG_ 2517073933 FW_datecode_7_22 "Character 7";
CM_ SG_ 2517073933 FW_datecode_8_22 "Character 8";
CM_ SG_ 2517073933 FW_datecode_9_22 "Character 9";
CM_ SG_ 2517073933 FW_datecode_10_22 "Character 10";
CM_ SG_ 2517073933 FW_datecode_11_22 "Character 11";
CM_ SG_ 2517073933 FW_datecode_12_22 "Character 12";
CM_ SG_ 2517073933 FW_datecode_13_22 "Character 13";
CM_ SG_ 2517073922 Status_Error_Code_22 "Main status / error code as defined in errno/errno.h";
CM_ SG_ 2517073922 Data_1_22 "Additional information for the error/status";
CM_ SG_ 2517073922 Data_2_22 "Additional information for the error/status";
CM_ SG_ 2517073922 Data_3_22 "Additional information for the error/status";
CM_ SG_ 2517073927 Running_22 "Indicates if converter is running.";
CM_ SG_ 2517073927 PWM_22 "Indicates if converter is in PWM control mode.";
CM_ SG_ 2517073927 Current_dc_loop_mode_22 "Indicates if the current DC loop is enabled.";
CM_ SG_ 2517073927 Current_ac_loop_mode_22 "Indicates if the current AC loop is enabled.";
CM_ SG_ 2517073927 Buck_22 "Indicates if converter is in buck control mode.";
CM_ SG_ 2517073927 Boost_22 "Indicates if converter is in boost control mode.";
CM_ SG_ 2517073927 Precharge_dc_buck_mode_22 "Indicates if the precharge DC mode is enabled - buck direction.";
CM_ SG_ 2517073927 Precharge_dc_boost_mode_22 "Indicates if the precharge DC mode is enabled - boost direction.";
CM_ SG_ 2517073927 Rectifier_3ph_22 "Indicates if converter is in three-phase rectifier control mode.";
CM_ SG_ 2517073927 Stack_mode_22 "Indicates if converter is operating in stack mode.";
CM_ SG_ 2517073927 Master_22 "Indicates if converter is master in the stack.";
CM_ SG_ 2517073927 Slave_22 "Indicates if converter is slave in the stack.";
CM_ SG_ 2517073927 Inverter_1ph_22 "Indicates if converter is in single-phase inverter control mode.";
CM_ SG_ 2517073927 Boost_Neutral_22 "Indicates if converter is in boost control mode with neutral generation.";
CM_ SG_ 2517073927 Rectifier_1ph_22 "Indicates if converter is in single-phase rectifier control mode.";
CM_ SG_ 2517073927 Inverter_3ph_22 "Indicates if converter is in three-phase inverter control mode.";
CM_ SG_ 2517073927 Ready_22 "Indicates if converter is ready for operation.";
CM_ SG_ 2517073927 Inverter_1ph_Sync_22 "Single-phase inverter control mode with phase synchronization.";
CM_ SG_ 2517073927 Neutral_22 "Open-loop neutral generation.";
CM_ SG_ 2517073927 Rectifier_1ph_Buck_22 "Single-phase rectifier with buck on one leg.";
CM_ SG_ 2517073927 Inverter_1ph_Boost_22 "Single-phase inverter with boost on one leg.";
CM_ SG_ 2517073927 Rectifier_distributed_22 "Not available at the moment";
CM_ SG_ 2517073927 MPPT_buck_22 "Not available at the moment";
CM_ SG_ 2517073927 MPPT_boost_22 "Not available at the moment";
CM_ SG_ 2517073927 Buck_2p_float_22 "Buck in phases L1 and L2. Phase L3 is left floating (high impedance)";
CM_ SG_ 2517073927 Inverter_1ph_Distributed_22 "Single-phase inverter mode  distributed";
CM_ SG_ 2517073926 Protection_trip_internal_22 "This flagg is asserted if the interlock is open due to an internal fault condition (self-protection)";
CM_ SG_ 2517073926 Protection_trip_external_22 "This flag is asserted if the interlock is open due to an external condition received in the module.";
CM_ SG_ 2517073926 Phase_U_overcurrent_22 "Indicates an overcurrent event on Phase U. The overcurrent event is triggered when the measured phase current is over the programmed current limit.";
CM_ SG_ 2517073926 Phase_U_overvoltage_22 "Indicates an overvoltage event on Phase U. The overvoltage event is triggered when the measured phase voltage is over the programmed voltage limit.";
CM_ SG_ 2517073926 Phase_U_undervoltage_22 "Indicates an undervoltage event on Phase U. The overvoltage event is triggered when the measured phase voltage is over the programmed voltage limit.";
CM_ SG_ 2517073926 Phase_V_overvoltage_22 "Indicates an overvoltage event on Phase V. The overvoltage event is triggered when the measured phase voltage is over the programmed voltage limit.";
CM_ SG_ 2517073926 Phase_V_undervoltage_22 "Indicates an undervoltage event on Phase U. The overvoltage event is triggered when the measured phase voltage is over the programmed voltage limit.";
CM_ SG_ 2517073926 Phase_V_overcurrent_22 "Indicates an overcurrent event on Phase U. The overcurrent event is triggered when the measured phase current is over the programmed current limit.";
CM_ SG_ 2517073926 Phase_W_overvoltage_22 "Indicates an overvoltage event on Phase U. The overvoltage event is triggered when the measured phase voltage is over the programmed voltage limit.";
CM_ SG_ 2517073926 Phase_W_undervoltage_22 "Indicates an undervoltage event on Phase U. The overvoltage event is triggered when the measured phase voltage is over the programmed voltage limit.";
CM_ SG_ 2517073926 Phase_W_overcurrent_22 "Indicates an overcurrent event on Phase U. The overcurrent event is triggered when the measured phase current is over the programmed current limit.";
CM_ SG_ 2517073926 DC_undervoltage_22 "DC bus undervoltage condition. The undervoltage condition is asserted when the measured dc bus voltage is under the programmed voltage limit.";
CM_ SG_ 2517073926 DC_overvoltage_22 "DC bus overvoltage condition. The overvoltage condition is asserted when the measured dc bus voltage is over the programmed voltage limit.";
CM_ SG_ 2517073926 MOSFET_overtemperature_22 "This flag is asserted when the temperature of the MOSFET block is too high.";
CM_ SG_ 2517073926 Inductor_overtemperature_22 "This flag is asserted when the temperature of the inductor block is too high.";
CM_ SG_ 2517073926 Keep_Alive_not_served_22 "The Keep Alive feature is enabled but it was not served with the periodic message.";
CM_ SG_ 2517073926 PLL_not_locked_22 "Flag asserted when in rectifier modes, the PLL went out of lock condition";
CM_ SG_ 2517073926 Measurement_system_failure_22 "The voltages/currents measurement system is malfunctionning, and readouts are not guaranteed to be accurate.";
CM_ SG_ 2517073926 EEPROM_failure_22 "The configuration EEPROM failed to load or save the module configuration.";
CM_ SG_ 2517073923 Phase_U_22 "Phase current is the MOSFET loop current, in the branch U of the converter.";
CM_ SG_ 2517073923 Phase_V_22 "Phase current is the MOSFET loop current, in the branch V of the converter.";
CM_ SG_ 2517073923 Phase_W_22 "Phase current is the MOSFET loop current, in the branch W of the converter.";
CM_ SG_ 2517073936 Bus_current_22 "DC Bus current is possitive when current goes from input to output";
CM_ SG_ 2517073934 Phase_U_22 "Phase current is the MOSFET loop current, in the branch U of the converter.";
CM_ SG_ 2517073934 Phase_V_22 "Phase current is the MOSFET loop current, in the branch V of the converter.";
CM_ SG_ 2517073934 Phase_W_22 "Phase current is the MOSFET loop current, in the branch W of the converter.";
CM_ SG_ 2517073934 Stack_position_22 "Sender Stack position";
CM_ SG_ 2517073934 Group_ID_22 "Sender Group ID";
CM_ SG_ 2517073931 Phase_U_22 "RMS Phase current is the MOSFET loop current, in the branch U of the converter.";
CM_ SG_ 2517073931 Phase_V_22 "RMS Phase current is the MOSFET loop current, in the branch V of the converter.";
CM_ SG_ 2517073931 Phase_W_22 "RMS Phase current is the MOSFET loop current, in the branch W of the converter.";
CM_ SG_ 2517073932 Frequency_22 "Frequency of Three-Phase system";
CM_ SG_ 2517073932 Phase_22 "Phase of Three-Phase system";
CM_ SG_ 2517073925 Temp_Bridge_22 "Temperature of the MOSFET block";
CM_ SG_ 2517073925 Temp_Inductors_22 "Temperature of the inductors";
CM_ SG_ 2517073928 Phase_U_22 "The actual PWM duty cycle setpoint";
CM_ SG_ 2517073928 Phase_V_22 "The actual PWM duty cycle setpoint";
CM_ SG_ 2517073928 Phase_W_22 "The actual PWM duty cycle setpoint";
CM_ SG_ 2517073929 Current_setpoint_22 "The actual current setpoint";
CM_ SG_ 2517073929 Voltage_setpoint_22 "The actual voltage setpoint";
CM_ SG_ 2517073929 Frequency_setpoint_22 "The actual frequency setpoint";
CM_ SG_ 2517041248 Keep_Alive_Enable_22 "If set to 1, module will expect to receive this message every second repeatedly, or it will stop operation";
CM_ SG_ 2517041216 Converter_ON_22 "Enable the converter.";
CM_ SG_ 2517041216 PWM_ON_22 "Enable the PWM control mode.";
CM_ SG_ 2517041216 DC_Current_feedback_ON_22 "Enable the DC current loop";
CM_ SG_ 2517041216 AC_Current_feedback_ON_22 "Enable the AC current loop";
CM_ SG_ 2517041216 Buck_ON_22 "Enable the buck control mode.";
CM_ SG_ 2517041216 Boost_ON_22 "Enable the boost control mode.";
CM_ SG_ 2517041216 Rectifier_3ph_ON_22 "Enable the three-phase rectifier control mode.";
CM_ SG_ 2517041216 Inverter_1ph_ON_22 "Enable the single-phase inverter control mode.";
CM_ SG_ 2517041216 Rectifier_1ph_ON_22 "Enable the single-phase rectifier control mode.";
CM_ SG_ 2517041216 Boost_Neutral_ON_22 "Enable the boost control mode with neutral generation.";
CM_ SG_ 2517041216 Inverter_3ph_ON_22 "Enable the three-phase inverter control mode.";
CM_ SG_ 2517041216 Inverter_1ph_Sync_ON_22 "Single-phase inverter control mode with phase synchronization.";
CM_ SG_ 2517041216 Neutral_ON_22 "Open-loop neutral generation.";
CM_ SG_ 2517041216 Rectifier_1ph_Buck_ON_22 "Single-phase rectifier with buck on one leg.";
CM_ SG_ 2517041216 Inverter_1ph_Boost_ON_22 "Single-phase inverter with boost on one leg.";
CM_ SG_ 2517041216 Rectifier_Distributed_ON_22 "Single-phase (floating) distributed rectifier";
CM_ SG_ 2517041216 MPPT_buck_ON_22 "MPPT buck";
CM_ SG_ 2517041216 MPPT_boost_ON_22 "MPPT boost";
CM_ SG_ 2517041216 Buck_2p_float_ON_22 "Boost on L1 and L2. Floating L3 (high-impedance)";
CM_ SG_ 2517041216 Inverter_1ph_Distributed_ON_22 "Single-phase inverter mode distributed";
CM_ SG_ 2517041232 Clear_Interlock_22 "Clears the converter interlock";
CM_ SG_ 2517041232 Reset_Processor_22 "Reset the converter DSP";
CM_ SG_ 2517041232 Trip_Interlock_22 "Trip the inetrnal Interlock";
CM_ SG_ 2517041217 Reactive_current_setpoint_22 "This defines reactive current setpoint for 3-phase rectifier mode";
CM_ SG_ 2517041218 Phase_U_22 "The actual PWM duty cycle setpoint";
CM_ SG_ 2517041218 Phase_V_22 "The actual PWM duty cycle setpoint";
CM_ SG_ 2517041218 Phase_W_22 "The actual PWM duty cycle setpoint";
CM_ SG_ 2517041219 Current_setpoint_22 "Sets the output current setpoint. Active only when the current loop is enabled";
CM_ SG_ 2517041220 Voltage_setpoint_22 "Sets the output voltage setpoint. Active only when the voltage loop is enabled";
CM_ SG_ 2517041224 Frequency_setpoint_22 "Sets the frequency for single-phase and three-phase generator modes.";
CM_ SG_ 2517041225 Phase_setpoint_22 "Sets the phase for inverter control modes.";
CM_ SG_ 2517041221 Stack_position_22 "The converter position within the stack";
CM_ SG_ 2517041221 Stack_size_22 "How many PFC converters are in stack in total";
CM_ SG_ 2517041221 SN_number_22 "Unique module serial number";
CM_ SG_ 2517041200 Phase_voltage_min_22 "Minimum tolerated phase voltage";
CM_ SG_ 2517041200 Phase_voltage_max_22 "Maximum allowable phase voltage";
CM_ SG_ 2517041200 DC_voltage_min_22 "Minimum allowable dc voltage";
CM_ SG_ 2517041200 DC_voltage_max_22 "Maximum allowable dc voltage";
CM_ SG_ 2517041201 Phase_current_min_22 "Minimum allowable output current";
CM_ SG_ 2517041201 Phase_current_max_22 "Maximum allowable output current";
CM_ SG_ 2517041228 Group_ID_22 "Desired group ID for the device";
CM_ SG_ 2517073935 Group_ID_22 "Group ID of the device";
CM_ SG_ 2517041249 Factory_mode_22 "Customers MUST NOT USE this bit. If set to 1, module will enter in factory mode. ";
CM_ SG_ 2517041249 Silent_CAN_mode_22 "Customers MUST NOT USE this bit. If set to 1, module will enter in factory mode. ";
CM_ SG_ 2517041226 start_22 "Start automatic calibration. Multiplexer index must be 0!";
CM_ SG_ 2517041227 point_22 "Calibration point index.";
CM_ SG_ 2517041222 CRC_22 "Checksum of bytes 0 to 3, CRC-CCITT, corresponding to qChecksum (www.qt.io)";
CM_ SG_ 2517041223 CRC_22 "Checksum of bytes 0 to 3, CRC-CCITT, corresponding to qChecksum (www.qt.io)";
CM_ SG_ 2517074006 Current_U_High_22 "This flag is set if a hight current on U tripped the internal interlock";
CM_ SG_ 2517074006 Current_U_Low_22 "This flag is set if a low current on U tripped the internal interlock";
CM_ SG_ 2517074006 Current_V_High_22 "This flag is set if a hight current on V tripped the internal interlock";
CM_ SG_ 2517074006 Current_V_Low_22 "This flag is set if a low current on V tripped the internal interlock";
CM_ SG_ 2517074006 Current_W_High_22 "This flag is set if a hight current on W tripped the internal interlock";
CM_ SG_ 2517074006 Current_W_Low_22 "This flag is set if a low current on W tripped the internal interlock";
CM_ SG_ 2517074006 Voltage_DC_22 "This flag is set if a voltage on DC tripped the internal interlock";
CM_ SG_ 2517074006 Reboot_22 "This flag is set if a reboot tripped the internal interlock";
CM_ SG_ 2517074006 Unknown_22 "This flag the reason for the internal interlock is unknown";

BA_DEF_ BO_ "SystemMessageLongSymbol" STRING;

BA_ "SystemMessageLongSymbol" BO_ 2517041217 "AFE_Reactive_Current_Setpoint_Control_22";
BA_ "SystemMessageLongSymbol" BO_ 2517041224 "AFE_Frequency_Setpoint_Control_22";
BA_ "SystemMessageLongSymbol" BO_ 2517041264 "AFE_Rectifier_Setpoint_Control_22";
BA_ "SystemMessageLongSymbol" BO_ 2517041222 "_AFE_Calibration_Offset_Update_22";

VAL_ 2517073920 Device_type_22 7 "AFE";
VAL_ 2517073926 Protection_trip_internal_22 1 "fault";
VAL_ 2517073926 Protection_trip_external_22 1 "fault";
VAL_ 2517073926 Phase_U_overcurrent_22 1 "fault";
VAL_ 2517073926 Phase_U_overvoltage_22 1 "fault";
VAL_ 2517073926 Phase_U_undervoltage_22 1 "fault";
VAL_ 2517073926 Phase_V_overvoltage_22 1 "fault";
VAL_ 2517073926 Phase_V_undervoltage_22 1 "fault";
VAL_ 2517073926 Phase_V_overcurrent_22 1 "fault";
VAL_ 2517073926 Phase_W_overvoltage_22 1 "fault";
VAL_ 2517073926 Phase_W_undervoltage_22 1 "fault";
VAL_ 2517073926 Phase_W_overcurrent_22 1 "fault";
VAL_ 2517073926 DC_undervoltage_22 1 "fault";
VAL_ 2517073926 DC_overvoltage_22 1 "fault";
VAL_ 2517073926 MOSFET_overtemperature_22 1 "fault";
VAL_ 2517073926 Inductor_overtemperature_22 1 "fault";
VAL_ 2517073926 Keep_Alive_not_served_22 1 "fault";
VAL_ 2517073926 PLL_not_locked_22 1 "fault";
VAL_ 2517073926 NFO_22 1 "fault";
VAL_ 2517073926 Measurement_system_failure_22 1 "fault";
VAL_ 2517073926 EEPROM_failure_22 1 "fault";
VAL_ 2517073926 System_22 1 "fault";
VAL_ 2517074006 Current_U_High_22 1 "fault";
VAL_ 2517074006 Current_U_Low_22 1 "fault";
VAL_ 2517074006 Current_V_High_22 1 "fault";
VAL_ 2517074006 Current_V_Low_22 1 "fault";
VAL_ 2517074006 Current_W_High_22 1 "fault";
VAL_ 2517074006 Current_W_Low_22 1 "fault";
VAL_ 2517074006 Voltage_DC_22 1 "fault";
VAL_ 2517074006 Reboot_22 1 "fault";
VAL_ 2517074006 Unknown_22 1 "fault";
SIG_VALTYPE_ 2517074001 Current_U_22 : 1;
SIG_VALTYPE_ 2517074001 Current_V_22 : 1;
SIG_VALTYPE_ 2517074001 Current_W_22 : 1;
SIG_VALTYPE_ 2517074001 Voltage_U_22 : 1;
SIG_VALTYPE_ 2517074001 Voltage_V_22 : 1;
SIG_VALTYPE_ 2517074001 Voltage_W_22 : 1;
SIG_VALTYPE_ 2517074001 Voltage_DC_22 : 1;
SIG_VALTYPE_ 2517074002 Current_U_22 : 1;
SIG_VALTYPE_ 2517074002 Current_V_22 : 1;
SIG_VALTYPE_ 2517074002 Current_W_22 : 1;
SIG_VALTYPE_ 2517074002 Voltage_U_22 : 1;
SIG_VALTYPE_ 2517074002 Voltage_V_22 : 1;
SIG_VALTYPE_ 2517074002 Voltage_W_22 : 1;
SIG_VALTYPE_ 2517074002 Voltage_DC_22 : 1;
